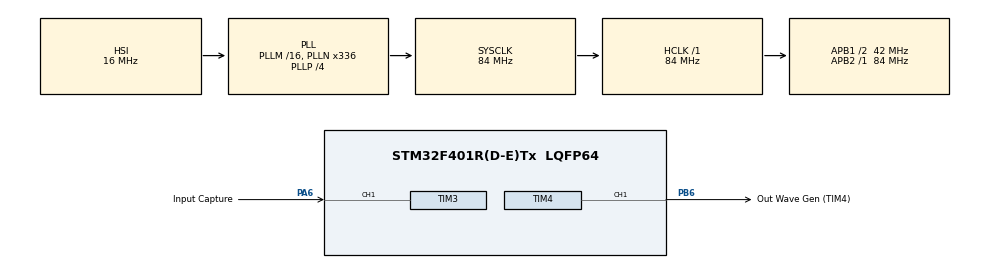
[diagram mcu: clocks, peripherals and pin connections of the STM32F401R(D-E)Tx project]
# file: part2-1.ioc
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Mcu.Family=STM32F4
Mcu.Name=STM32F401R(D-E)Tx
Mcu.Package=LQFP64
NVIC.PriorityGroup=NVIC_PRIORITYGROUP_0
NVIC.TIM3_IRQn=true\:0\:0\:false\:false\:true\:true\:true\:true
PA6.GPIO_Label=Input Capture
PA6.Signal=S_TIM3_CH1
PB6.GPIO_Label=Out Wave Gen (TIM4)
PB6.Signal=S_TIM4_CH1
ProjectManager.HeapSize=0x200
ProjectManager.StackSize=0x400
ProjectManager.TargetToolchain=STM32CubeIDE
RCC.AHBFreq_Value=84000000
RCC.APB1CLKDivider=RCC_HCLK_DIV2
RCC.APB1Freq_Value=42000000
RCC.APB1TimFreq_Value=84000000
RCC.APB2Freq_Value=84000000
RCC.APB2TimFreq_Value=84000000
RCC.CortexFreq_Value=84000000
RCC.HCLKFreq_Value=84000000
RCC.HSE_VALUE=8000000
RCC.HSI_VALUE=16000000
RCC.LSE_VALUE=32768
RCC.PLLN=336
RCC.PLLP=RCC_PLLP_DIV4
RCC.PLLQ=7
RCC.SYSCLKFreq_VALUE=84000000
RCC.SYSCLKSource=RCC_SYSCLKSOURCE_PLLCLK
RCC.VCOOutputFreq_Value=336000000
SH.S_TIM3_CH1.0=TIM3_CH1,Input_Capture1_from_TI1
SH.S_TIM4_CH1.0=TIM4_CH1,PWM Generation1 CH1
TIM3.Channel-Input_Capture1_from_TI1=TIM_CHANNEL_1
TIM3.Prescaler=99
TIM4.Channel-PWM\ Generation1\ CH1=TIM_CHANNEL_1
TIM4.Period=8399
TIM4.Prescaler=0
TIM4.Pulse-PWM\ Generation1\ CH1=4200
VP_TIM3_VS_ClockSourceINT.Mode=Internal
VP_TIM4_VS_ClockSourceINT.Mode=Internal
board=NUCLEO-F401RE

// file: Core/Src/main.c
/* USER CODE BEGIN Header */
/**
 ******************************************************************************
 * @file           : main.c
 * @brief          : Main program body
 ******************************************************************************
 * @attention
 *
 * Copyright (c) 2025 STMicroelectronics.
 * All rights reserved.
 *
 * This software is licensed under terms that can be found in the LICENSE file
 * in the root directory of this software component.
 * If no LICENSE file comes with this software, it is provided AS-IS.
 *
 ******************************************************************************
 */
/* USER CODE END Header */
#include "main.h"

TIM_HandleTypeDef htim3;
TIM_HandleTypeDef htim4;

void SystemClock_Config(void);
static void MX_GPIO_Init(void);
static void MX_TIM3_Init(void);
static void MX_TIM4_Init(void);

/* USER CODE BEGIN 0 */
static volatile float in_wave_freq;
/* USER CODE END 0 */

int main(void) {

	/* MCU Configuration--------------------------------------------------------*/

	/* Reset of all peripherals, Initializes the Flash interface and the Systick. */
	HAL_Init();

	/* Configure the system clock */
	SystemClock_Config();

	/* USER CODE BEGIN SysInit */

	__HAL_DBGMCU_FREEZE_TIM3();
	__HAL_DBGMCU_FREEZE_TIM4();

	/* USER CODE END SysInit */

	/* Initialize all configured peripherals */
	MX_GPIO_Init();
	MX_TIM3_Init();
	MX_TIM4_Init();
	/* USER CODE BEGIN 2 */

	// HAL_TIM_PWM_Start(&htim2, TIM_CHANNEL_1); // generazione segnale esterno
	HAL_TIM_PWM_Start(&htim4, TIM_CHANNEL_1); // 10kHz PWM in uscita

	HAL_TIM_Base_Start_IT(&htim3);
	HAL_TIM_IC_Start_IT(&htim3, TIM_CHANNEL_1);

	/* USER CODE END 2 */

	/* Infinite loop */
	/* USER CODE BEGIN WHILE */
	float out_wave_dc; // duty cycle di TIM4, PWM, CH1

	while (1) {
		if (800.f <= in_wave_freq && in_wave_freq <= 12000.f) {
			out_wave_dc = (in_wave_freq - 800.f) * (0.75f - 0.25f)
					/ (12000.f - 800.f) + 0.25f;

			// il canale è stato configurato in modo da avere Pulse = 8400 * Duty cycle
			__HAL_TIM_SET_COMPARE(&htim4, TIM_CHANNEL_1,
					(int ) (out_wave_dc * (htim4.Init.Period + 1)));

		} else {
			// segnala l'errore impostando DC = 10%
			__HAL_TIM_SET_COMPARE(&htim4, TIM_CHANNEL_1,
					10 * (htim4.Init.Period + 1));
		}

		/* USER CODE END WHILE */

	}
}

void SystemClock_Config(void) {
	RCC_OscInitTypeDef RCC_OscInitStruct = { 0 };
	RCC_ClkInitTypeDef RCC_ClkInitStruct = { 0 };

	/** Configure the main internal regulator output voltage
	 */
	__HAL_RCC_PWR_CLK_ENABLE();
	__HAL_PWR_VOLTAGESCALING_CONFIG(PWR_REGULATOR_VOLTAGE_SCALE2);

	/** Initializes the RCC Oscillators according to the specified parameters
	 * in the RCC_OscInitTypeDef structure.
	 */
	RCC_OscInitStruct.OscillatorType = RCC_OSCILLATORTYPE_HSI;
	RCC_OscInitStruct.HSIState = RCC_HSI_ON;
	RCC_OscInitStruct.HSICalibrationValue = RCC_HSICALIBRATION_DEFAULT;
	RCC_OscInitStruct.PLL.PLLState = RCC_PLL_ON;
	RCC_OscInitStruct.PLL.PLLSource = RCC_PLLSOURCE_HSI;
	RCC_OscInitStruct.PLL.PLLM = 16;
	RCC_OscInitStruct.PLL.PLLN = 336;
	RCC_OscInitStruct.PLL.PLLP = RCC_PLLP_DIV4;
	RCC_OscInitStruct.PLL.PLLQ = 7;
	if (HAL_RCC_OscConfig(&RCC_OscInitStruct) != HAL_OK) {
		Error_Handler();
	}

	/** Initializes the CPU, AHB and APB buses clocks
	 */
	RCC_ClkInitStruct.ClockType = RCC_CLOCKTYPE_HCLK | RCC_CLOCKTYPE_SYSCLK
			| RCC_CLOCKTYPE_PCLK1 | RCC_CLOCKTYPE_PCLK2;
	RCC_ClkInitStruct.SYSCLKSource = RCC_SYSCLKSOURCE_PLLCLK;
	RCC_ClkInitStruct.AHBCLKDivider = RCC_SYSCLK_DIV1;
	RCC_ClkInitStruct.APB1CLKDivider = RCC_HCLK_DIV2;
	RCC_ClkInitStruct.APB2CLKDivider = RCC_HCLK_DIV1;

	if (HAL_RCC_ClockConfig(&RCC_ClkInitStruct, FLASH_LATENCY_2) != HAL_OK) {
		Error_Handler();
	}
}

static void MX_TIM3_Init(void) {

	TIM_ClockConfigTypeDef sClockSourceConfig = { 0 };
	TIM_MasterConfigTypeDef sMasterConfig = { 0 };
	TIM_IC_InitTypeDef sConfigIC = { 0 };

	htim3.Instance = TIM3;
	htim3.Init.Prescaler = 99;
	htim3.Init.CounterMode = TIM_COUNTERMODE_UP;
	htim3.Init.Period = 65535;
	htim3.Init.ClockDivision = TIM_CLOCKDIVISION_DIV1;
	htim3.Init.AutoReloadPreload = TIM_AUTORELOAD_PRELOAD_DISABLE;
	if (HAL_TIM_Base_Init(&htim3) != HAL_OK) {
		Error_Handler();
	}
	sClockSourceConfig.ClockSource = TIM_CLOCKSOURCE_INTERNAL;
	if (HAL_TIM_ConfigClockSource(&htim3, &sClockSourceConfig) != HAL_OK) {
		Error_Handler();
	}
	if (HAL_TIM_IC_Init(&htim3) != HAL_OK) {
		Error_Handler();
	}
	sMasterConfig.MasterOutputTrigger = TIM_TRGO_RESET;
	sMasterConfig.MasterSlaveMode = TIM_MASTERSLAVEMODE_DISABLE;
	if (HAL_TIMEx_MasterConfigSynchronization(&htim3, &sMasterConfig)
			!= HAL_OK) {
		Error_Handler();
	}
	sConfigIC.ICPolarity = TIM_INPUTCHANNELPOLARITY_RISING;
	sConfigIC.ICSelection = TIM_ICSELECTION_DIRECTTI;
	sConfigIC.ICPrescaler = TIM_ICPSC_DIV1;
	sConfigIC.ICFilter = 0;
	if (HAL_TIM_IC_ConfigChannel(&htim3, &sConfigIC, TIM_CHANNEL_1) != HAL_OK) {
		Error_Handler();
	}

}

static void MX_TIM4_Init(void) {

	TIM_ClockConfigTypeDef sClockSourceConfig = { 0 };
	TIM_MasterConfigTypeDef sMasterConfig = { 0 };
	TIM_OC_InitTypeDef sConfigOC = { 0 };

	htim4.Instance = TIM4;
	htim4.Init.Prescaler = 0;
	htim4.Init.CounterMode = TIM_COUNTERMODE_UP;
	htim4.Init.Period = 8399;
	htim4.Init.ClockDivision = TIM_CLOCKDIVISION_DIV1;
	htim4.Init.AutoReloadPreload = TIM_AUTORELOAD_PRELOAD_DISABLE;
	if (HAL_TIM_Base_Init(&htim4) != HAL_OK) {
		Error_Handler();
	}
	sClockSourceConfig.ClockSource = TIM_CLOCKSOURCE_INTERNAL;
	if (HAL_TIM_ConfigClockSource(&htim4, &sClockSourceConfig) != HAL_OK) {
		Error_Handler();
	}
	if (HAL_TIM_PWM_Init(&htim4) != HAL_OK) {
		Error_Handler();
	}
	sMasterConfig.MasterOutputTrigger = TIM_TRGO_RESET;
	sMasterConfig.MasterSlaveMode = TIM_MASTERSLAVEMODE_DISABLE;
	if (HAL_TIMEx_MasterConfigSynchronization(&htim4, &sMasterConfig)
			!= HAL_OK) {
		Error_Handler();
	}
	sConfigOC.OCMode = TIM_OCMODE_PWM1;
	sConfigOC.Pulse = 4200;
	sConfigOC.OCPolarity = TIM_OCPOLARITY_HIGH;
	sConfigOC.OCFastMode = TIM_OCFAST_DISABLE;
	if (HAL_TIM_PWM_ConfigChannel(&htim4, &sConfigOC, TIM_CHANNEL_1)
			!= HAL_OK) {
		Error_Handler();
	}
	HAL_TIM_MspPostInit(&htim4);

}

static void MX_GPIO_Init(void) {

	/* GPIO Ports Clock Enable */
	__HAL_RCC_GPIOA_CLK_ENABLE();
	__HAL_RCC_GPIOB_CLK_ENABLE();

}

/* USER CODE BEGIN 4 */

static uint32_t tim3_overflows = 0;

void HAL_TIM_PeriodElapsedCallback(TIM_HandleTypeDef *htim) {
	if (htim->Instance == TIM3) {
		tim3_overflows++;
	}
}

void HAL_TIM_IC_CaptureCallback(TIM_HandleTypeDef *htim) {
	static uint32_t previous = 0;

	uint32_t capture, diff;

	if (htim->Instance == TIM3) {
		capture = HAL_TIM_ReadCapturedValue(htim, TIM_CHANNEL_1);

		diff = tim3_overflows * htim3.Init.Period + (capture - previous);
		tim3_overflows = 0;
		previous = capture;

		in_wave_freq = 84e6 / ((float) diff * (htim3.Init.Prescaler + 1));
	}
}

/* USER CODE END 4 */

void Error_Handler(void) {
	__disable_irq();
	while (1) {
	}
}
